# WKUP_CTRL_MMR0_CFG0 register map
Vendor: Texas Instruments
Registers are 32-bit, access per field, reset 0x0 unless marked. A register's access mark holds for its fields unless they carry their own. Offsets are as the file gives them; [hi:lo] are bit positions; lines under a group give offsets from that group; {n}, {i} and the like mark numbered series; 'fields as' and 'values as' point back to an identical list.

## WKUP_CTRL_MMR0_CFG0 (part 2 of 2)
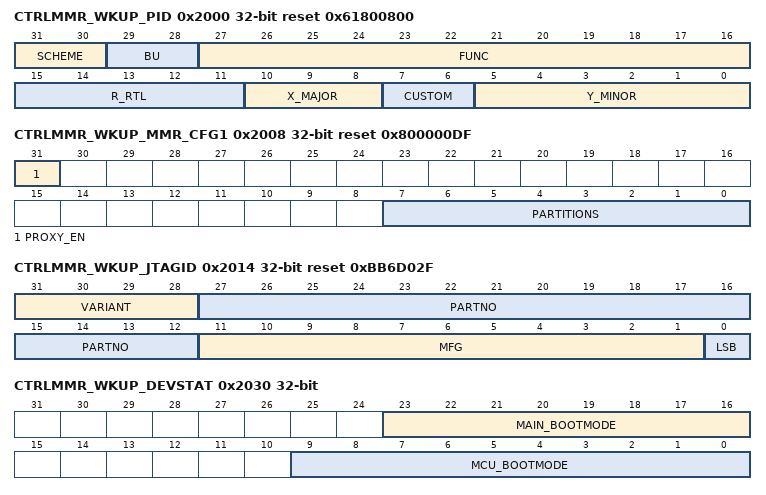
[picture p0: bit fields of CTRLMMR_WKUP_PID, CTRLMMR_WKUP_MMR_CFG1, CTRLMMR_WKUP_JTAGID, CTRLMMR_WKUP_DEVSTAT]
0x2000 CTRLMMR_WKUP_PID ro reset 0x61800800
  [31:30] SCHEME
  [29:28] BU — Business unit - Processors
  [27:16] FUNC — Module functional identifier - CTRL MMR
  [15:11] R_RTL — RTL revision number - actual value determined by RTL
  [10:8] X_MAJOR — Major revision number - actual value determined by RTL
  [7:6] CUSTOM — Custom revision number - actual value determined by RTL
  [5:0] Y_MINOR — Minor revision number - actual value determined by RTL
0x2008 CTRLMMR_WKUP_MMR_CFG1 ro reset 0x800000DF
  [31] PROXY_EN — Proxy addressing enabled
  [7:0] PARTITIONS — Indicates present partitions
0x2014 CTRLMMR_WKUP_JTAGID ro reset 0xBB6D02F
  [31:28] VARIANT — Used to indicate new PGs
  [27:12] PARTNO — Part number for boundary scan
  [11:1] MFG — Indicates manufacturer
  [0] LSB — Always 1
{0x2020+4i} CTRLMMR_WKUP_DIE_ID{i} ro reset not defined (i=0..3)
  [31:0] DIEID — Contains individual die information
0x2030 CTRLMMR_WKUP_DEVSTAT (reset mask 0xFF00FC00)
  [23:16] MAIN_BOOTMODE rw — Specifies the device Primary and Backup boot media.
  [9:0] MCU_BOOTMODE rw — Indicates MCU boot mode.
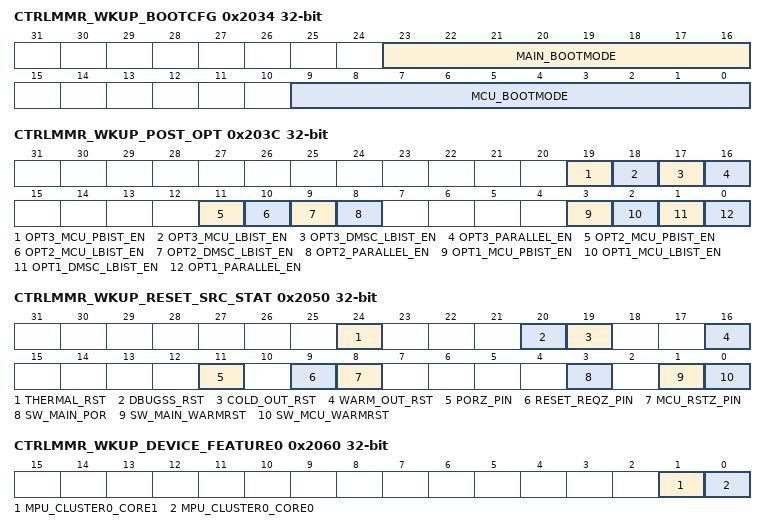
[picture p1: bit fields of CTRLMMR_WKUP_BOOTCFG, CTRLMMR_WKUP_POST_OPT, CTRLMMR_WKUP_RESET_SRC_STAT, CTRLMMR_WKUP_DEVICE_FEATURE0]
0x2034 CTRLMMR_WKUP_BOOTCFG ro (reset mask 0xFF00FC00)
  [23:16] MAIN_BOOTMODE — Specifies the device Primary and Backup boot media as latched at PORz
  [9:0] MCU_BOOTMODE — Indicates MCU boot mode as latched at power-on reset. These bits always contain the values latched.Bits 9:8 - Power-on Self Test mode (if
0x2038 CTRLMMR_WKUP_POST_SEL_STAT ro (reset mask 0xFFFFFFFC)
  [1:0] POST_SEL_STAT — Indicates which POST option was selected at power-up
0x203C CTRLMMR_WKUP_POST_OPT ro (reset mask 0xFFF0F0F0)
  [19] OPT3_MCU_PBIST_EN — MCU R5 PBIST enabled
  [18] OPT3_MCU_LBIST_EN — MCU R5 LBIST enabled
  [17] OPT3_DMSC_LBIST_EN — DMSC LBIST enabled
  [16] OPT3_PARALLEL_EN — Selects DMSC/MCU R5 LBIST sequencing
  [11] OPT2_MCU_PBIST_EN — MCU R5 PBIST enabled
  [10] OPT2_MCU_LBIST_EN — MCU R5 LBIST enabled
  [9] OPT2_DMSC_LBIST_EN — DMSC LBIST enabled
  [8] OPT2_PARALLEL_EN — Selects DMSC/MCU R5 LBIST sequencing
  [3] OPT1_MCU_PBIST_EN — MCU R5 PBIST enabled
  [2] OPT1_MCU_LBIST_EN — MCU R5 LBIST enabled
  [1] OPT1_DMSC_LBIST_EN — DMSC LBIST enabled
  [0] OPT1_PARALLEL_EN — Selects DMSC/MCU R5 LBIST sequencing
0x2050 CTRLMMR_WKUP_RESET_SRC_STAT access not given
  [24] THERMAL_RST — When set, indicates that a VTM Max Temp Thermal reset occurred. (access REC)
  [20] DBUGSS_RST — When set, indicates that a Debug reset occurred. (access FEC)
  [19] COLD_OUT_RST — When set, indicates that a DMSC Cold reset occurred. (access FEC)
  [16] WARM_OUT_RST — When set, indicates that a DSMC Warm reset occurred. (access FEC)
  [11] PORZ_PIN — When set indicates that a PORz pin reset occurred. (access FEC)
  [9] RESET_REQZ_PIN — When set indicates that a RESET_REQz pin reset occurred. (access FEC)
  [8] MCU_RSTZ_PIN — When set indicates that a MCU_RESETz pin reset occurred. (access FEC)
  [3] SW_MAIN_POR — When set, indicates that a Software MAIN Power-on reset occurred. (access FEC)
  [1] SW_MAIN_WARMRST — When set indicates that a Software MAIN Warm reset occurred. (access FEC)
  [0] SW_MCU_WARMRST — When set indicates that a Software MCU Warm reset occurred. (access FEC)
0x2060 CTRLMMR_WKUP_DEVICE_FEATURE0 ro (reset mask 0xFFFFFFFC)
  [1] MPU_CLUSTER0_CORE1 — MPU Cluster0 Core 1 is enabled when set
  [0] MPU_CLUSTER0_CORE0 — MPU Cluster0 Core 0 is enabled when set
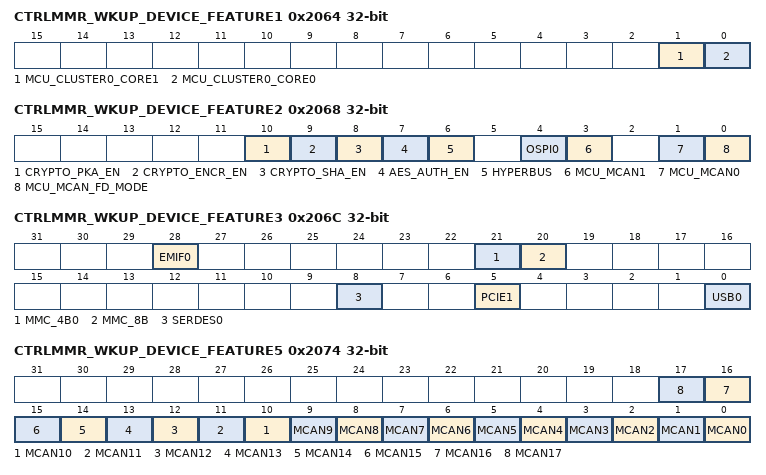
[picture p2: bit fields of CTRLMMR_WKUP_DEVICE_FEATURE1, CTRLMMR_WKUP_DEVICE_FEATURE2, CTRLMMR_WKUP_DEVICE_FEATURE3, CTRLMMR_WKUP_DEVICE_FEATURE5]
0x2064 CTRLMMR_WKUP_DEVICE_FEATURE1 ro (reset mask 0xFFFFFFFC)
  [1] MCU_CLUSTER0_CORE1 — MAIN MCU Cluster0 Core1 is enabled when set
  [0] MCU_CLUSTER0_CORE0 — MAIN MCU Cluster0 Core0 is enabled when set
0x2068 CTRLMMR_WKUP_DEVICE_FEATURE2 ro (reset mask 0xFFFFF804)
  [10] CRYPTO_PKA_EN — MCU SA2_UL Crypto Module PKA enabled
  [9] CRYPTO_ENCR_EN — MCU SA2_UL Crypto Module AES/3DES/DBRG enabled
  [8] CRYPTO_SHA_EN — MCU SA2_UL Crypto Module SHA/MD5 enabled
  [7] AES_AUTH_EN — AES authentication is enabled in MCU_FlashSS and DMSC when set
  [6] HYPERBUS — MCU_Hyperbus is enabled when set
  [4] OSPI0 — MCU_OSPI0 is enabled when set
  [3] MCU_MCAN1 — MCU_MCAN1 is enabled when set
  [1] MCU_MCAN0 — MCU_MCAN0 is enabled when set
  [0] MCU_MCAN_FD_MODE — FD mode is supported on MCU_MCAN[1:0] when set
0x206C CTRLMMR_WKUP_DEVICE_FEATURE3 ro (reset mask 0xEFCFFEDE)
  [28] EMIF0 — EMIF0 is enabled when set
  [21] MMC_4B0 — 4-bit MMC/SD1 is enabled when set
  [20] MMC_8B — 8-bit MMC/SD0 is enabled when set
  [8] SERDES0 — 10G SERDES0 is enabled when set
  [5] PCIE1 — PCIe1 is enabled when set
  [0] USB0 — USB0 is enabled when set
0x2074 CTRLMMR_WKUP_DEVICE_FEATURE5 ro (reset mask 0xFFFC0000)
  [n] MCAN{n} (n=0..17) — MCAN{n} is enabled when set
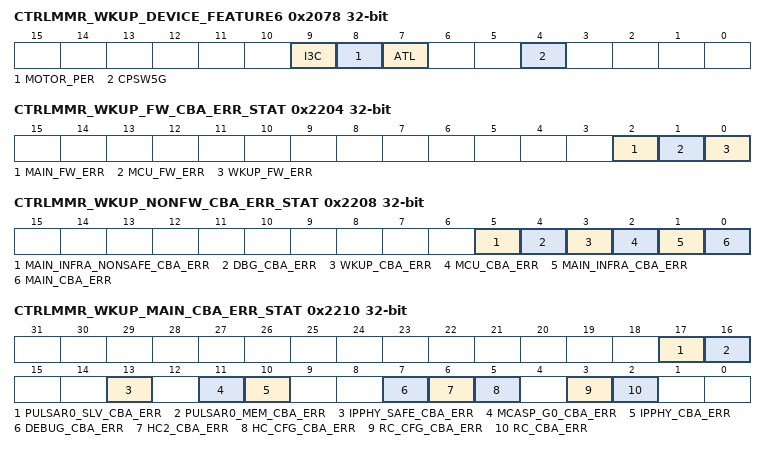
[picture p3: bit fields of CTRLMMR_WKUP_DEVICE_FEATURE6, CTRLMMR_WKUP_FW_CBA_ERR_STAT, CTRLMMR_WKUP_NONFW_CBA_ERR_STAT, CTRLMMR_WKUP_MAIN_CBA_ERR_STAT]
0x2078 CTRLMMR_WKUP_DEVICE_FEATURE6 ro (reset mask 0xFF8FFC6F)
  [9] I3C — MAIN domain I3C is enabled when set
  [8] MOTOR_PER — Motor control peripherals (eCAP, eQEP, eHRPWM) are enabled when set
  [7] ATL — Audio tracking logic is enabled when set
  [4] CPSW5G — 4 Channel Q/SGMII Ethernet switch enabled when set
0x2200 CTRLMMR_WKUP_DBG_CBA_ERR_STAT ro (reset mask 0xFFFFFFFD)
  [1] MAIN_DBG_ERR — Main Debug bus segment error
0x2204 CTRLMMR_WKUP_FW_CBA_ERR_STAT ro (reset mask 0xFFFFFFF8)
  [2] MAIN_FW_ERR — MAIN Firewall bus segment error
  [1] MCU_FW_ERR — MCU Firewall bus segment error
  [0] WKUP_FW_ERR — WKUP Firewall bus segment error
0x2208 CTRLMMR_WKUP_NONFW_CBA_ERR_STAT ro (reset mask 0xFFFFFFC0)
  [5] MAIN_INFRA_NONSAFE_CBA_ERR — MAIN Infrastructure non-safe bus segment error
  [4] DBG_CBA_ERR — Debug bus aggregated error. See
  [3] WKUP_CBA_ERR — WKUP Data bus segment error
  [2] MCU_CBA_ERR — MCU Data bus segment error
  [1] MAIN_INFRA_CBA_ERR — MAIN Infrastructure safe bus segment error
  [0] MAIN_CBA_ERR — MAIN Data bus aggregated error. See
0x2210 CTRLMMR_WKUP_MAIN_CBA_ERR_STAT ro (reset mask 0xFFFCD313)
  [17] PULSAR0_SLV_CBA_ERR — MAIN R5 Slave Data bus segment error
  [16] PULSAR0_MEM_CBA_ERR — MAIN R5 Memory Data bus segment error
  [13] IPPHY_SAFE_CBA_ERR — MAIN Phy safe Data bus segment error
  [11] MCASP_G0_CBA_ERR — MAIN McASP Group0 Data bus segment error
  [10] IPPHY_CBA_ERR — MAIN Phy non-safe Data bus segment error
  [7] DEBUG_CBA_ERR — MAIN Debug Data bus segment error
  [6] HC2_CBA_ERR — MAIN HC2 Data bus segment error
  [5] HC_CFG_CBA_ERR — MAIN HC CFG Data bus segment error
  [3] RC_CFG_CBA_ERR — MAIN RC CFG Data bus segment error
  [2] RC_CBA_ERR — MAIN RC Data bus segment error
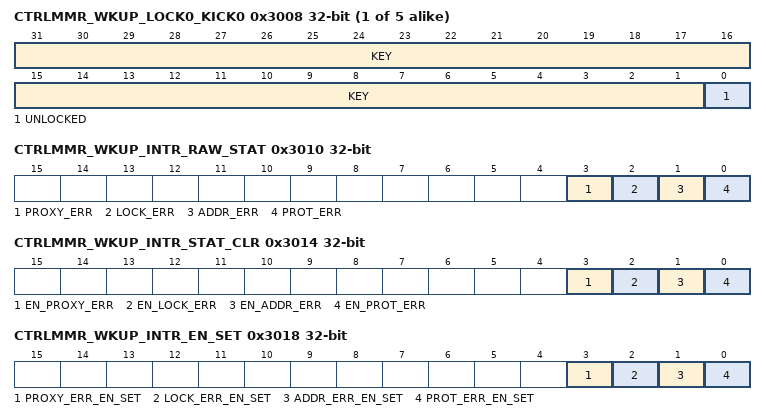
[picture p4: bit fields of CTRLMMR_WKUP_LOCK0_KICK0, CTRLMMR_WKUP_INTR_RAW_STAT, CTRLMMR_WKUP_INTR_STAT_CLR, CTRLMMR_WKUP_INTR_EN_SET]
{0x3008+0x4000*i} CTRLMMR_WKUP_LOCK{i}_KICK0 (i=0..4)
  [31:1] KEY rw — Write the kick0 unlock value followed by the kick1 unlock value to unlock the write-protected Partition{i} registers
  [0] UNLOCKED ro — Unlock status.
{0x300C+0x4000*i} CTRLMMR_WKUP_LOCK{i}_KICK1 rw (i=0..4)
  [31:0] KEY — Write the kick1 unlock value after the kick0 unlock value to unlock the write-protected Partition{i} registers
0x3010 CTRLMMR_WKUP_INTR_RAW_STAT access not given
  [3] PROXY_ERR — Proxy violation occurred (attempt to write a Proxy1 claimed register through its Proxy0 address) (access W1TS)
  [2] LOCK_ERR — Lock violation occurred (attempt to write a write-locked register with partition locked) (access W1TS)
  [1] ADDR_ERR — Address violation occurred (attempt to read or write an invalid register address) (access W1TS)
  [0] PROT_ERR — Protection violation occurred (attempt to read or write a register with insufficient security or privilege access rights) (access W1TS)
0x3014 CTRLMMR_WKUP_INTR_STAT_CLR access not given
  [3] EN_PROXY_ERR — Enabled proxy interrupt event status (access W1TC)
  [2] EN_LOCK_ERR — Enabled lock interrupt event status (access W1TC)
  [1] EN_ADDR_ERR — Enabled address interrupt event status (access W1TC)
  [0] EN_PROT_ERR — Enabled protection interrupt event status (access W1TC)
0x3018 CTRLMMR_WKUP_INTR_EN_SET access not given
  [3] PROXY_ERR_EN_SET — Proxy interrupt enable (access W1TS)
  [2] LOCK_ERR_EN_SET — Lock interrupt enable (access W1TS)
  [1] ADDR_ERR_EN_SET — Address interrupt enable (access W1TS)
  [0] PROT_ERR_EN_SET — Protection interrupt enable (access W1TS)
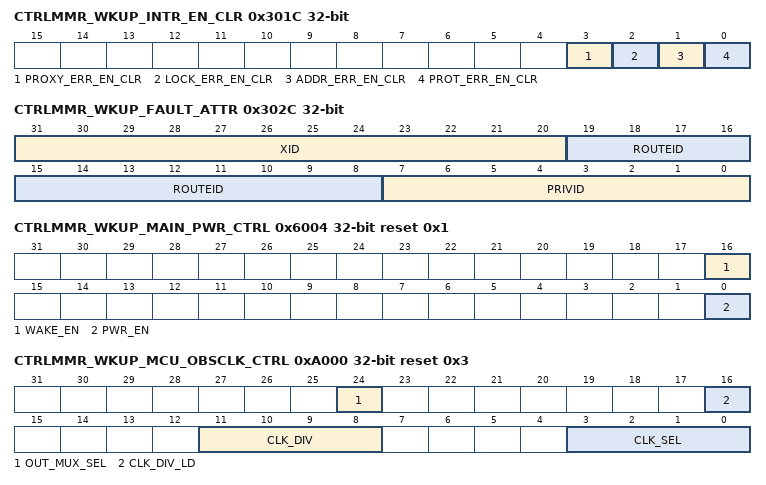
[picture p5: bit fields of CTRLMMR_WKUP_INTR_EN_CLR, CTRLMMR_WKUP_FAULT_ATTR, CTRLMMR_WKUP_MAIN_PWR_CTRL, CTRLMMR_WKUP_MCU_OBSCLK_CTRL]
0x301C CTRLMMR_WKUP_INTR_EN_CLR access not given
  [3] PROXY_ERR_EN_CLR — Proxy interrupt disable (access W1TC)
  [2] LOCK_ERR_EN_CLR — Lock interrupt disable (access W1TC)
  [1] ADDR_ERR_EN_CLR — Address interrupt disable (access W1TC)
  [0] PROT_ERR_EN_CLR — Protection interrupt disable (access W1TC)
0x3020 CTRLMMR_WKUP_EOI
  [7:0] VECTOR rw
0x3024 CTRLMMR_WKUP_FAULT_ADDR ro
  [31:0] ADDRESS — Address of the faulted access
0x3028 CTRLMMR_WKUP_FAULT_TYPE ro
  [5:0] TYPE — Type of access which faulted 0h - No fault 1h - User execute access 2h - User write access 4h - User read access 8h - Supervisor execute access 10h - Supervisor write access 20h - Supervisor read access
0x302C CTRLMMR_WKUP_FAULT_ATTR ro
  [31:20] XID — Transaction ID
  [19:8] ROUTEID
  [7:0] PRIVID — Privilege ID
0x3030 CTRLMMR_WKUP_FAULT_CLR access not given
  [0] CLEAR — Fault clear (access W1TC)
{0x3100+4i} CTRLMMR_WKUP_P0_CLAIM{i} rw (i=0..5)
  [31:0] PROXY1_CLAIMED — Proxy1 register claim bit
0x6004 CTRLMMR_WKUP_MAIN_PWR_CTRL reset 0x1
  [16] WAKE_EN rw — When set, drives the PMIC_WAKE0 output (low).
  [0] PWR_EN rw — When set, drives the PMIC_PWR_EN1 output to turn on the MAIN voltage domain
0x6008 CTRLMMR_WKUP_MCU_PWR_CTRL
  [16] WAKE_EN rw — When set, drives the PMIC_WAKE1 output (low).
0x6020 CTRLMMR_WKUP_GPIO_CTRL
  [0] WAKEN rw — Enables WKUP_GPIO wakeup event operation by controlling the WKUP_GPIO LPSC clockstop_ack behavior. 0h - No WKUP_GPIO wakeup support. WKUP_GPIO vbus clock is gated on clkstop_ack from WKUP_GPIO to LPSC 1h - WKUP_GPIO wakeup enabled. WKUP_GPIO vbus clock is NOT gated on LPSC clockstop_req. WKUP_GPIO LPSC clkstop_ack input is driven by clkstop_req output.
0x6030 CTRLMMR_WKUP_I2C0_CTRL
  [0] HS_MCS_EN rw — HS Mode master current source enable.
{0x6080+4i} CTRLMMR_WKUP_DBOUNCE_CFG{i} (i=1..6)
  [5:0] DB_CFG rw — Configures the debounce period used for I/Os with DEBOUNCE_SEL{i} enabled.
0x7100 CTRLMMR_WKUP_P1_CLAIM0 rw
  [31:0] PROXY1_CLAIMED — Proxy1 register claim bit
0x7104 CTRLMMR_WKUP_P1_CLAIM1 rw
  [31:0] PROXY1_CLAIMED — Proxy1 register claim bit
0xA000 CTRLMMR_WKUP_MCU_OBSCLK_CTRL reset 0x3
  [24] OUT_MUX_SEL rw — MCU_OBSCLK pin output mux selection.
  [16] CLK_DIV_LD rw — Load the output divider value
  [11:8] CLK_DIV rw — MCU_OBSCLK pin clock selection output divider
  [3:0] CLK_SEL rw — MCU_OBSCLK pin clock selection 0h - CLK_12M_RC 1h - '0' 2h - MCU_PLL0_HSDIV0_CLKOUT 3h - MCU_PLLCTL_OBSCLK 4h - MCU_PLL1_HSDIV1_CLKOUT 5h - MCU_PLL1_HSDIV2_CLKOUT 6h - MCU_PLL1_HSDIV3_CLKOUT 7h - MCU_PLL1_HSDIV4_CLKOUT 8h - MCU_PLL2_HSDIV0_CLKOUT 9h - CLK_32K Ah - MCU_PLL2_HSDIV1_CLKOUT Bh - MCU_PLL2_HSDIV2_CLKOUT Ch - MCU_PLL2_HSDIV3_CLKOUT Dh - MCU_PLL2_HSDIV4_CLKOUT Eh - HFOSC0_CLKOUT Fh - WKUP_LFOSC0_CLKOUT
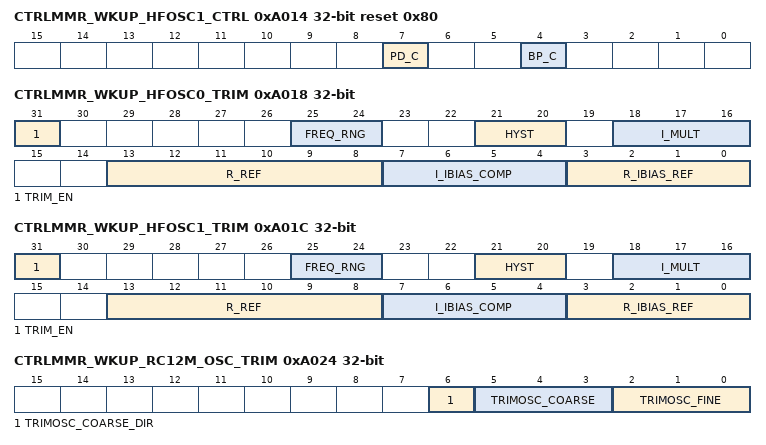
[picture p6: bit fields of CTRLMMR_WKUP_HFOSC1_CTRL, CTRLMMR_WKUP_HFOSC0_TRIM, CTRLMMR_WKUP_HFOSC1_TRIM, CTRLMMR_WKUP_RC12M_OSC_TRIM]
0xA014 CTRLMMR_WKUP_HFOSC1_CTRL reset 0x80
  [7] PD_C rw — Oscillator powerdown control. When set, oscillator is disabled. Oscillator output is tristated if bp_c=0
  [4] BP_C rw — Oscillator bypass control. When set oscillator is in bypass mode
0xA018 CTRLMMR_WKUP_HFOSC0_TRIM (reset mask 0x7CC8C000)
  [31] TRIM_EN rw — Apply MMR values to OSC trim inputs instead of tie-offs
  [25:24] FREQ_RNG rw — Sets the frequency range of operation based on: 0h - I(AMP) - 3x I(MIRRBIAS) 1h - I(AMP) 2h - I(AMP) 3h - I(AMP) + 3x I(MIRRBIAS)
  [21:20] HYST rw — Sets comparator hysteresis
  [18:16] I_MULT rw — AGC AMP current multiplication gain 0h - 3x I(MIRRBIAS) 1h - 4x I(MIRRBIAS) 2h - 5x I(MIRRBIAS) 3h - 6x I(MIRRBIAS) 4h - 7x I(MIRRBIAS) 5h - 8x I(MIRRBIAS) 6h - 9x I(MIRRBIAS) 7h - 10x I(MIRRBIAS)
  [13:8] R_REF rw — Sets the AMP AGC bias current 0h - 0.00 K-Ohm 1h - 3.1548 K-Ohm 2h - 6.3048 K-Ohm 3h - 9.4548 K-Ohm 4h - 12.6048 K-Ohm 5h - 15.7548 K-Ohm 6h - 18.9048 K-Ohm 7h - 22.0548 K-Ohm
  [7:4] I_IBIAS_COMP rw — Sets the COMP bias current 0h - 40x 1h - 48x 2h - 56x 3h - 64x 4h - 72x 5h - 80x 6h - 88x 7h - 96x 8h - 104x 9h - 112x Ah - 120x Bh - 128x Ch - 136x Dh - 144x Eh - 152x Fh - 160x
  [3:0] R_IBIAS_REF rw — Sets the base IBIAS reference 0h - 64 K-Ohm 1h - 72 K-Ohm 2h - 80 K-Ohm 3h - 88 K-Ohm 4h - 96 K-Ohm 5h - 104 K-Ohm 6h - 112 K-Ohm 7h - 120 K-Ohm 8h - 128 K-Ohm 9h - 136 K-Ohm Ah - 144 K-Ohm Bh - 152 K-Ohm Ch - 160 K-Ohm Dh - 168 K-Ohm Eh - 176 K-Ohm Fh - 184 K-Ohm
0xA01C CTRLMMR_WKUP_HFOSC1_TRIM (reset mask 0x7CC8C000)
  fields as CTRLMMR_WKUP_HFOSC0_TRIM
0xA024 CTRLMMR_WKUP_RC12M_OSC_TRIM (reset mask 0xFFFFFF80)
  [6] TRIMOSC_COARSE_DIR rw — Coarse adjustment direction. If output is greater than 12.5
  [5:3] TRIMOSC_COARSE rw — Coarse adjustment. Frequency is decreased or increased by 1.25 MHz per value based on the trimosc_coarse_dir value.
  [2:0] TRIMOSC_FINE rw — Fine adjustment. Decreases the frequency by 250 KHz per value.
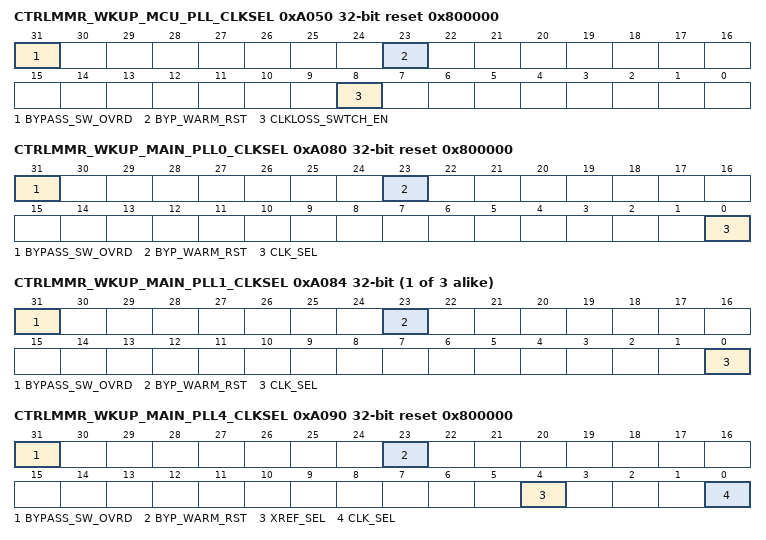
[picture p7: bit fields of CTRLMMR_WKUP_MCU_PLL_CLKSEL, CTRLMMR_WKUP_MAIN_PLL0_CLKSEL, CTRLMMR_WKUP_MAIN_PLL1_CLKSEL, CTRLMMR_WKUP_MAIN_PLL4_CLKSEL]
0xA050 CTRLMMR_WKUP_MCU_PLL_CLKSEL reset 0x800000
  [31] BYPASS_SW_OVRD rw — PLL Bypass warm reset software override
  [23] BYP_WARM_RST rw — PLL bypass mode after warm reset.
  [8] CLKLOSS_SWTCH_EN rw — When set, enables automatic switching of MCU PLL[2:0] clock source to CLK_12M_RC if HFOSC0 clock loss is detected
0xA060 CTRLMMR_WKUP_PER_CLKSEL
  [0] MCUPLL_BYPASS rw — Select the main oscillator clock rather than the PLL generated clock as the functional clock (PLL BYPASS mode).
0xA064 CTRLMMR_WKUP_USART_CLKSEL
  [0] CLK_SEL rw — WKUP_USART0 FCLK selection
0xA070 CTRLMMR_WKUP_GPIO_CLKSEL
  [1:0] WAKE_CLK_SEL rw — WKUP_GPIO clock selection. Must be set to MCU_SYSCLK0/6 whenever WKUP_GPIO VBUS interface is enabled. Other clock source may be selected as a wake up clock for DeepSleep modes after WKUP_GPIO is gated off through LPSC. 0h - MCU_SYSCLK0 / 6 1h - MCU_SYSCLK0 / 6 2h - CLK_32K 3h - CLK_12M_RC
0xA080 CTRLMMR_WKUP_MAIN_PLL0_CLKSEL reset 0x800000
  [31] BYPASS_SW_OVRD rw — PLL Bypass warm reset software override
  [23] BYP_WARM_RST rw — PLL bypass mode after warm reset.
  [0] CLK_SEL rw — Selects the clock source for MAIN PLL0
{0xA080+4i} CTRLMMR_WKUP_MAIN_PLL{i}_CLKSEL (i=1..3)
  [31] BYPASS_SW_OVRD rw — PLL Bypass warm reset software override
  [23] BYP_WARM_RST rw — PLL bypass mode after warm reset.
  [0] CLK_SEL rw — Selects the clock source for MAIN PLL{i}
0xA090 CTRLMMR_WKUP_MAIN_PLL4_CLKSEL reset 0x800000
  [31] BYPASS_SW_OVRD rw — PLL Bypass warm reset software override
  [23] BYP_WARM_RST rw — PLL bypass mode after warm reset.
  [4] XREF_SEL rw — Selects the alternate clock source for MAIN PLL4
  [0] CLK_SEL rw — Selects the clock source for MAIN PLL4
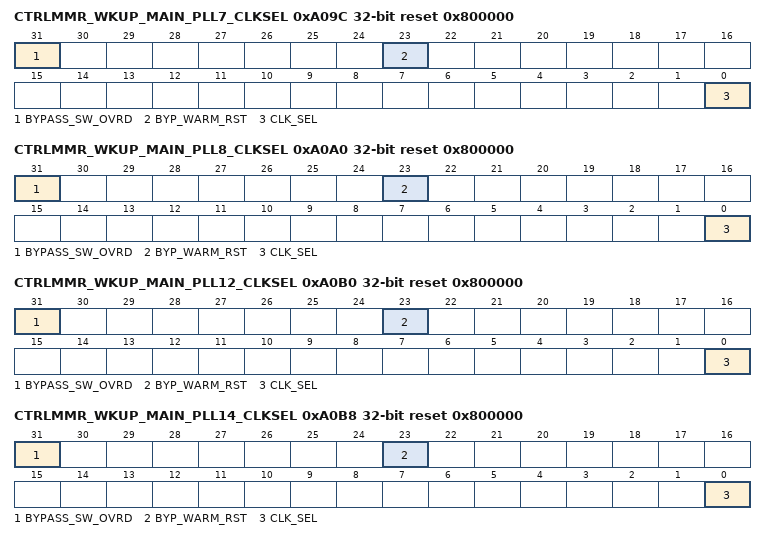
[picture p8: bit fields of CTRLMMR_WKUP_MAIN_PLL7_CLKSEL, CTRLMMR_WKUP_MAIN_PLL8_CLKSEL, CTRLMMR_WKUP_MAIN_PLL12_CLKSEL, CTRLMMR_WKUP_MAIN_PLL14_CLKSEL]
0xA09C CTRLMMR_WKUP_MAIN_PLL7_CLKSEL reset 0x800000
  [31] BYPASS_SW_OVRD rw — PLL Bypass warm reset software override
  [23] BYP_WARM_RST rw — PLL bypass mode after warm reset.
  [0] CLK_SEL rw — Selects the clock source for MAIN PLL7
0xA0A0 CTRLMMR_WKUP_MAIN_PLL8_CLKSEL reset 0x800000
  [31] BYPASS_SW_OVRD rw — PLL Bypass warm reset software override
  [23] BYP_WARM_RST rw — PLL bypass mode after warm reset.
  [0] CLK_SEL rw — Selects the clock source for MAIN PLL8
0xA0B0 CTRLMMR_WKUP_MAIN_PLL12_CLKSEL reset 0x800000
  [31] BYPASS_SW_OVRD rw — PLL Bypass warm reset software override
  [23] BYP_WARM_RST rw — PLL bypass mode after warm reset.
  [0] CLK_SEL rw — Selects the clock source for MAIN PLL12
0xA0B8 CTRLMMR_WKUP_MAIN_PLL14_CLKSEL reset 0x800000
  [31] BYPASS_SW_OVRD rw — PLL Bypass warm reset software override
  [23] BYP_WARM_RST rw — PLL bypass mode after warm reset.
  [0] CLK_SEL rw — Selects the clock source for MAIN PLL14
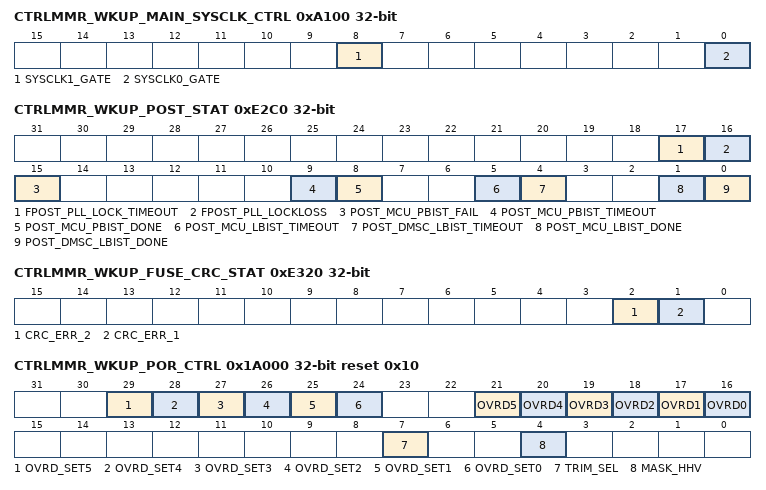
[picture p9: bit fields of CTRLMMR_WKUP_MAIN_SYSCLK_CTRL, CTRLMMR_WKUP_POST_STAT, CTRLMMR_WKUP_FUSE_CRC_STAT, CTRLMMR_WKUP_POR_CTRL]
0xA100 CTRLMMR_WKUP_MAIN_SYSCLK_CTRL
  [8] SYSCLK1_GATE rw — When set, gates off SYSCLK1 output of the MAIN PLL Controller
  [0] SYSCLK0_GATE rw — When set, gates off SYSCLK0 (MCLK1) output of the MAIN PLL Controller
0xA110 CTRLMMR_WKUP_MCU_SPI0_CLKSEL
  [16] MSTR_LB_CLKSEL rw — Master mode receive capture clock loopback selection
0xA114 CTRLMMR_WKUP_MCU_SPI1_CLKSEL
  fields as CTRLMMR_WKUP_MCU_SPI0_CLKSEL
{0xB100+4i} CTRLMMR_WKUP_P2_CLAIM{i} rw (i=0..2)
  [31:0] PROXY1_CLAIMED — Proxy1 register claim bit
0xE280 CTRLMMR_WKUP_DMSC_LBIST_SIG ro reset not defined
  [31:0] MISR_SIG — MISR signature
0xE2C0 CTRLMMR_WKUP_POST_STAT ro (reset mask 0xFFFC7CCC)
  [17] FPOST_PLL_LOCK_TIMEOUT — Indicates PLL lock timeout for Fast POST mode operation.
  [16] FPOST_PLL_LOCKLOSS — Indicates if PLL lock was lost during POST
  [15] POST_MCU_PBIST_FAIL — MCU PBIST failed
  [9] POST_MCU_PBIST_TIMEOUT — MCU PBIST timed out
  [8] POST_MCU_PBIST_DONE — MCU PBIST done
  [5] POST_MCU_LBIST_TIMEOUT — MCU LBIST timed out
  [4] POST_DMSC_LBIST_TIMEOUT — DMSC LBIST timed out
  [1] POST_MCU_LBIST_DONE — MCU LBIST done
  [0] POST_DMSC_LBIST_DONE — DMSC LBIST done
0xE320 CTRLMMR_WKUP_FUSE_CRC_STAT ro (reset mask 0xFFFFFFF9)
  [2] CRC_ERR_2 — Indicates eFuse CRC error on chain 2
  [1] CRC_ERR_1 — Indicates eFuse CRC error on chain 1
{0xF100+4i} CTRLMMR_WKUP_P3_CLAIM{i} rw (i=1..6)
  [31:0] PROXY1_CLAIMED — Proxy1 register claim bit
0x13108 CTRLMMR_WKUP_P4_CLAIM2 rw
  [31:0] PROXY1_CLAIMED — Proxy1 register claim bit
0x1310C CTRLMMR_WKUP_P4_CLAIM3 rw
  [31:0] PROXY1_CLAIMED — Proxy1 register claim bit
0x13114 CTRLMMR_WKUP_P4_CLAIM5 rw
  [31:0] PROXY1_CLAIMED — Proxy1 register claim bit
0x1311C CTRLMMR_WKUP_P4_CLAIM7 rw
  [31:0] PROXY1_CLAIMED — Proxy1 register claim bit
0x1A000 CTRLMMR_WKUP_POR_CTRL reset 0x10
  [29] OVRD_SET5 rw — Reserved override set
  [28] OVRD_SET4 rw — POKLVB override set
  [27] OVRD_SET3 rw — POKLVA override set
  [26] OVRD_SET2 rw — POKHV override set
  [25] OVRD_SET1 rw — BGOK override set
  [24] OVRD_SET0 rw — PORHV override set
  [21] OVRD5 rw — Reserved override enable
  [20] OVRD4 rw — POKLVB override enable
  [19] OVRD3 rw — POKLVA override enable
  [18] OVRD2 rw — POKHV override enable
  [17] OVRD1 rw — BGOK override enable
  [16] OVRD0 rw — PORHV override enable
  [7] TRIM_SEL rw — POR Trim Select
  [4] MASK_HHV rw — Mask HHV/SOC_PORz outputs when applying new trim values
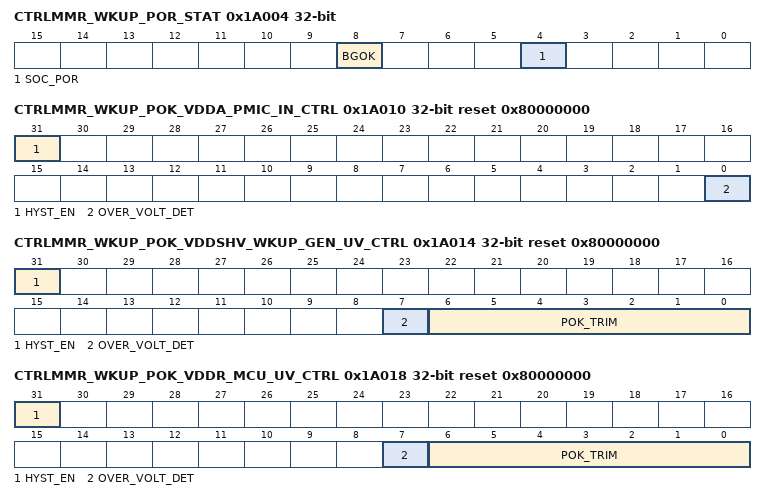
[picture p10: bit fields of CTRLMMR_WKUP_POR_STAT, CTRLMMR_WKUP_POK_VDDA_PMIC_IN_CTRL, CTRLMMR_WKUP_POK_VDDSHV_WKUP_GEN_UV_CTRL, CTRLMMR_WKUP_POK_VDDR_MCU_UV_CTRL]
0x1A004 CTRLMMR_WKUP_POR_STAT ro (reset mask 0xFFFFFEEF)
  [8] BGOK — Bandgap OK status
  [4] SOC_POR — POR module status
0x1A010 CTRLMMR_WKUP_POK_VDDA_PMIC_IN_CTRL reset 0x80000000
  [31] HYST_EN rw — Enable POK hysteresis
  [0] OVER_VOLT_DET rw — Over / under voltage detection mode
0x1A014 CTRLMMR_WKUP_POK_VDDSHV_WKUP_GEN_UV_CTRL reset 0x80000000 (reset mask 0xFFFFFF00)
  [31] HYST_EN rw — Enable POK hysteresis
  [7] OVER_VOLT_DET rw — Over / under voltage detection mode
  [6:0] POK_TRIM rw — POK trim bits. These bits are used to trim the comparator threshold voltage.
0x1A018 CTRLMMR_WKUP_POK_VDDR_MCU_UV_CTRL reset 0x80000000 (reset mask 0xFFFFFF00)
  fields as CTRLMMR_WKUP_POK_VDDSHV_WKUP_GEN_UV_CTRL
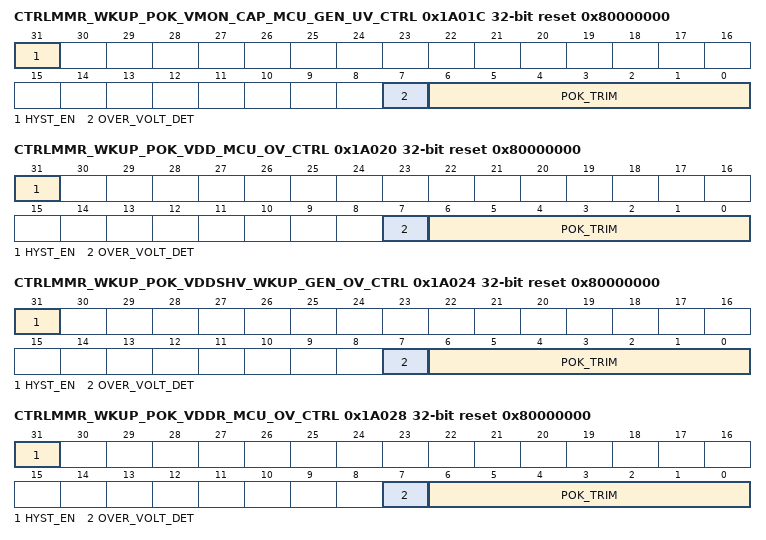
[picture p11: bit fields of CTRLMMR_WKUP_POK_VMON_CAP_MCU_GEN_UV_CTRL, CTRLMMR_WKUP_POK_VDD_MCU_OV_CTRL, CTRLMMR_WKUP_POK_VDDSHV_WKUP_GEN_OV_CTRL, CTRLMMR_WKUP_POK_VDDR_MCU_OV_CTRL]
0x1A01C CTRLMMR_WKUP_POK_VMON_CAP_MCU_GEN_UV_CTRL reset 0x80000000 (reset mask 0xFFFFFF00)
  fields as CTRLMMR_WKUP_POK_VDDSHV_WKUP_GEN_UV_CTRL
0x1A020 CTRLMMR_WKUP_POK_VDD_MCU_OV_CTRL reset 0x80000000 (reset mask 0xFFFFFF00)
  fields as CTRLMMR_WKUP_POK_VDDSHV_WKUP_GEN_UV_CTRL
0x1A024 CTRLMMR_WKUP_POK_VDDSHV_WKUP_GEN_OV_CTRL reset 0x80000000 (reset mask 0xFFFFFF00)
  fields as CTRLMMR_WKUP_POK_VDDSHV_WKUP_GEN_UV_CTRL
0x1A028 CTRLMMR_WKUP_POK_VDDR_MCU_OV_CTRL reset 0x80000000 (reset mask 0xFFFFFF00)
  fields as CTRLMMR_WKUP_POK_VDDSHV_WKUP_GEN_UV_CTRL
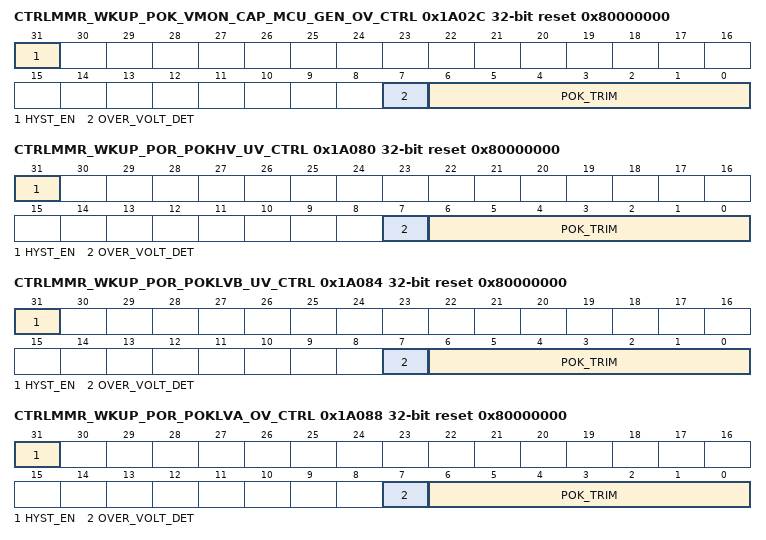
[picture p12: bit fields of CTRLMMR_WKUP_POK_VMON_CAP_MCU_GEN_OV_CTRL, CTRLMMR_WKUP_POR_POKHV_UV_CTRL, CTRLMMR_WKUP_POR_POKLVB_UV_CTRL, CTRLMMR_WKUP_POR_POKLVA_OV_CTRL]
0x1A02C CTRLMMR_WKUP_POK_VMON_CAP_MCU_GEN_OV_CTRL reset 0x80000000 (reset mask 0xFFFFFF00)
  fields as CTRLMMR_WKUP_POK_VDDSHV_WKUP_GEN_UV_CTRL
0x1A070 CTRLMMR_WKUP_MAIN_VDOM_CTRL
  [0] MAIN_VD_OFF rw — MAIN deep sleep isolation enable. This bit should be set prior to powering off the MAIN voltage domain to ensure proper signal isolation.
0x1A080 CTRLMMR_WKUP_POR_POKHV_UV_CTRL reset 0x80000000 (reset mask 0xFFFFFF00)
  fields as CTRLMMR_WKUP_POK_VDDSHV_WKUP_GEN_UV_CTRL
0x1A084 CTRLMMR_WKUP_POR_POKLVB_UV_CTRL reset 0x80000000 (reset mask 0xFFFFFF00)
  fields as CTRLMMR_WKUP_POK_VDDSHV_WKUP_GEN_UV_CTRL
0x1A088 CTRLMMR_WKUP_POR_POKLVA_OV_CTRL reset 0x80000000 (reset mask 0xFFFFFF00)
  fields as CTRLMMR_WKUP_POK_VDDSHV_WKUP_GEN_UV_CTRL
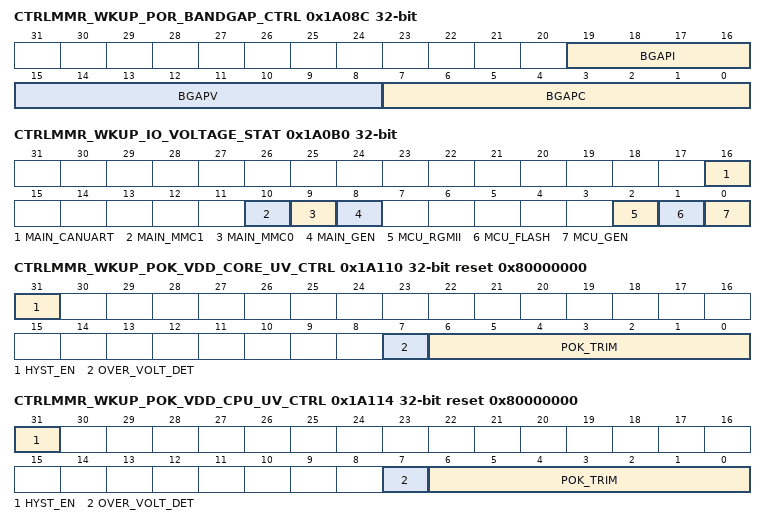
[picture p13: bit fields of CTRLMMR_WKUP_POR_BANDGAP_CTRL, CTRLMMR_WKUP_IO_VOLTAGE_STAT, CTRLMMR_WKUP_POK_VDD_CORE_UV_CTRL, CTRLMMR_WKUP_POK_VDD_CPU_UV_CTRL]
0x1A08C CTRLMMR_WKUP_POR_BANDGAP_CTRL (reset mask 0xFFF00000)
  [19:16] BGAPI rw — Bandgap output current trim bits
  [15:8] BGAPV rw — Bandgap output voltage magnitude trim bits
  [7:0] BGAPC rw — Bandgap slope trim bits. Bit7 is used to calculate the offset
0x1A0A0 CTRLMMR_WKUP_TEMP_DIODE_TRIM (reset mask 0xFFFFC000)
  [13:0] TRIM rw — Sets the diode non-ideality factor (n), starting from 100th place decimal and going down
0x1A0B0 CTRLMMR_WKUP_IO_VOLTAGE_STAT ro (reset mask 0xFFFEF8F8)
  [16] MAIN_CANUART — Indicates the voltage for the CANUART I/O group
  [10] MAIN_MMC1 — Indicates the voltage for the MMC1 I/O group
  [9] MAIN_MMC0 — Indicates the voltage for the MMC0 I/O group
  [8] MAIN_GEN — Indicates the voltage for the General I/O group
  [2] MCU_RGMII — Indicates the voltage for the MCU CPSW2G RGMII I/O group
  [1] MCU_FLASH — Indicates the voltage for the MCU Flash I/O group
  [0] MCU_GEN — Indicates the voltage for the MCU General I/O group
0x1A104 CTRLMMR_WKUP_MAIN_POR_TO_CTRL (reset mask 0xFFFFFFF8)
  [2:0] TIMEOUT_PER rw — MAIN PORz hardware timeout period. 0h - Immediate 1h - 100 microsec 2h - 200 microsec 3h - 300 microsec 4h - 400 microsec 5h - 500 microsec
0x1A110 CTRLMMR_WKUP_POK_VDD_CORE_UV_CTRL reset 0x80000000 (reset mask 0xFFFFFF00)
  fields as CTRLMMR_WKUP_POK_VDDSHV_WKUP_GEN_UV_CTRL
0x1A114 CTRLMMR_WKUP_POK_VDD_CPU_UV_CTRL reset 0x80000000 (reset mask 0xFFFFFF00)
  fields as CTRLMMR_WKUP_POK_VDDSHV_WKUP_GEN_UV_CTRL
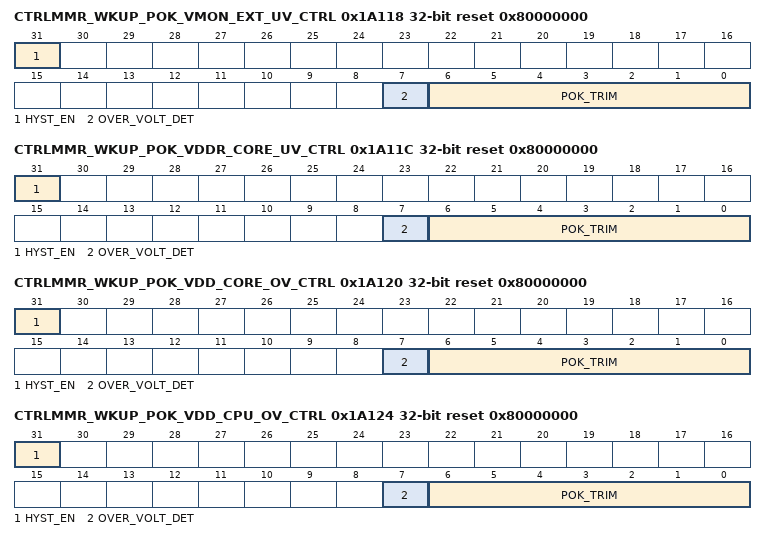
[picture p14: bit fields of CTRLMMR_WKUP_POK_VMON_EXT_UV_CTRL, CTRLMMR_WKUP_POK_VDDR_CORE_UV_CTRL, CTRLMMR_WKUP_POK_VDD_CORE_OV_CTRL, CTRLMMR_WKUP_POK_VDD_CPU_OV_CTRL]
0x1A118 CTRLMMR_WKUP_POK_VMON_EXT_UV_CTRL reset 0x80000000 (reset mask 0xFFFFFF00)
  fields as CTRLMMR_WKUP_POK_VDDSHV_WKUP_GEN_UV_CTRL
0x1A11C CTRLMMR_WKUP_POK_VDDR_CORE_UV_CTRL reset 0x80000000 (reset mask 0xFFFFFF00)
  fields as CTRLMMR_WKUP_POK_VDDSHV_WKUP_GEN_UV_CTRL
0x1A120 CTRLMMR_WKUP_POK_VDD_CORE_OV_CTRL reset 0x80000000 (reset mask 0xFFFFFF00)
  fields as CTRLMMR_WKUP_POK_VDDSHV_WKUP_GEN_UV_CTRL
0x1A124 CTRLMMR_WKUP_POK_VDD_CPU_OV_CTRL reset 0x80000000 (reset mask 0xFFFFFF00)
  fields as CTRLMMR_WKUP_POK_VDDSHV_WKUP_GEN_UV_CTRL
0x1A128 CTRLMMR_WKUP_POK_VMON_EXT_OV_CTRL reset 0x80000000 (reset mask 0xFFFFFF00)
  fields as CTRLMMR_WKUP_POK_VDDSHV_WKUP_GEN_UV_CTRL
0x1A12C CTRLMMR_WKUP_POK_VDDR_CORE_OV_CTRL reset 0x80000000 (reset mask 0xFFFFFF00)
  fields as CTRLMMR_WKUP_POK_VDDSHV_WKUP_GEN_UV_CTRL
0x1A130 CTRLMMR_WKUP_POK_VMON_EXT_MAIN1P8_UV_CTRL reset 0x80000000 (reset mask 0xFFFFFF00)
  fields as CTRLMMR_WKUP_POK_VDDSHV_WKUP_GEN_UV_CTRL
0x1A134 CTRLMMR_WKUP_POK_VMON_EXT_MAIN1P8_OV_CTRL reset 0x80000000 (reset mask 0xFFFFFF00)
  fields as CTRLMMR_WKUP_POK_VDDSHV_WKUP_GEN_UV_CTRL
0x1A138 CTRLMMR_WKUP_POK_VMON_EXT_MAIN3P3_UV_CTRL reset 0x80000000 (reset mask 0xFFFFFF00)
  fields as CTRLMMR_WKUP_POK_VDDSHV_WKUP_GEN_UV_CTRL
0x1A13C CTRLMMR_WKUP_POK_VMON_EXT_MAIN3P3_OV_CTRL reset 0x80000000 (reset mask 0xFFFFFF00)
  fields as CTRLMMR_WKUP_POK_VDDSHV_WKUP_GEN_UV_CTRL
0x1A160 CTRLMMR_WKUP_DEEPSLEEP_CTRL
  [8] FORCE_DS_MAIN rw — Force all MAIN IOs into deepsleep mode when set
  [0] FORCE_DS_WKUP rw — Force all WKUP IOs into deepsleep mode when set
0x1A170 CTRLMMR_WKUP_POR_RST_CTRL reset 0xF0000
  [24] MAIN_PORZ_DAISYCHAIN_EN rw — MAIN PORz daisy-chain event enable.
  [19:16] SW_MAIN_POR rw — Main Domain software power-on reset. When set to 6h, a power-on is issued to the MAIN voltage domain. (Bits will reset to Fh on reset of the Main Domain)
  [12] MAIN_PORZ_DS_STRETCH rw — DeepSleep mode MAIN PORz stretch.
  [0] POR_RST_ISO_DONE_Z rw — Reset isolation completion (active low). This bit should be cleared only after reset isolation of the MAIN domain is complete.
0x1A174 CTRLMMR_WKUP_MAIN_WARM_RST_CTRL reset 0xF0000
  [19:16] SW_WARMRST rw — Main Domain software warm reset. When set to 6h, a warm reset is issued to the MAIN voltage domain. (Bits will reset to Fh on reset of the Main Domain)
  [0] SOC_WARMRST_ISO_DONE_Z rw — Reset isolation completion (active low). This bit should be cleared only after reset isolation of the MAIN domain is complete.
0x1A178 CTRLMMR_WKUP_RST_STAT ro (reset mask 0xFFFEFFFE)
  [16] MCU_RST_DONE — Indicates MCU domain reset status.
  [0] MAIN_RST_DONE — Indicates MAIN domain Warm reset status.
0x1A17C CTRLMMR_WKUP_MCU_WARM_RST_CTRL reset 0xF0000
  [19:16] SW_WARMRST rw — Chip software warm reset. When set to 6h, a warm reset is issued to the device (all voltage domains). (Bits will reset to Fh on reset completion.)
0x1A180 CTRLMMR_WKUP_VDD_CPU_GLDTC_CTRL (reset mask 0xFFF8C0C0)
  [31] PWDB rw — Power down - active low.
  [30] RSTB rw — Reset - active low. To ensure proper operation, rstb must not be de-asserted for at least 100 ns after power-up (pwdb de-asserted). Additionally, rstb must be toggled low at least 200 ns after any change in threshold or low-pass filter settings to prevent abnormal trigger events.
  [18:16] LP_FILTER_SEL rw — Selects the glitch detect low-pass filter bandwidth 0h - 150 kHz 1h - 125 kHz 2h - 100 kHz 3h - 80 kHz 4h - 60 kHz 5h - 45 kHz 6h - 30 kHz 7h - 15 kHz
  [13:8] THRESH_HI_SEL rw — Selects the high voltage glitch threshold as a percentage of the monitored voltage 0h - 93.5% of VDD 1h - 94.0% of VDD 2h - 94.5% of VDD 3h - 95.0% of VDD 4h - 95.5% of VDD 5h - 96.0% of VDD 6h - 96.5% of VDD 7h - 97.0% of VDD 8h - 97.5% of VDD 9h - 98.0% of VDD Ah - 98.5% of VDD Bh - 99.0% of VDD Ch - 99.5% of VDD Dh - 100.0% of VDD Eh - 100.5% of VDD Fh - 101.0% of VDD 10h - 101.5% of VDD 11h - 102.0% of VDD 12h - 102.5% of VDD 13h - 103.0% of VDD 14h - 103.5% of VDD 15h - 104.0% of VDD 16h - 104.5% of VDD 17h - 105.0% of VDD 18h - 105.5% of VDD 19h - 106.0% of VDD 1Ah - 106.5% of VDD 1Bh - 107.0% of VDD 1Ch - 107.5% of VDD 1Dh - 108.0% of VDD 1Eh - 108.5% of VDD 1Fh - 109.0% of VDD 20h - 109.5% of VDD 21h - 110.0% of VDD 22h - 111.0% of VDD 23h - 112.0% of VDD 24h - 113.0% of VDD 25h - 114.0% of VDD 26h - 115.0% of VDD 27h - 116.0% of VDD 28h - 117.0% of VDD 29h - 118.0% of VDD 2Ah - 119.0% of VDD 2Bh - 120.0% of VDD 2Ch - 121.0% of VDD 2Dh - 122.0% of VDD 2Eh - 123.0% of VDD 2Fh - 124.0% of VDD 30h - 125.0% of VDD 31h - 126.0% of VDD 32h - 127.0% of VDD 33h - 128.0% of VDD 34h - 129.0% of VDD 35h - 130.0% of VDD 36h - 131.0% of VDD 37h - 132.0% of VDD 38h - 133.0% of VDD 39h - 134.0% of VDD 3Ah - 135.0% of VDD 3Bh - 136.0% of VDD 3Ch - 137.0% of VDD 3Dh - 138.0% of VDD 3Eh - 139.0% of VDD 3Fh - 140.0% of VDD
  [5:0] THRESH_LO_SEL rw — Selects the low voltage glitch threshold as a percentage of the monitored voltage 0h - 106.5% of VDD 1h - 106.0% of VDD 2h - 105.5% of VDD 3h - 105.0% of VDD 4h - 104.5% of VDD 5h - 104.0% of VDD 6h - 103.5% of VDD 7h - 103.0% of VDD 8h - 102.5% of VDD 9h - 102.0% of VDD Ah - 101.5% of VDD Bh - 101.0% of VDD Ch - 100.5% of VDD Dh - 100.0% of VDD Eh - 99.5% of VDD Fh - 99.0% of VDD 10h - 98.5% of VDD 11h - 98.0% of VDD 12h - 97.5% of VDD 13h - 97.0% of VDD 14h - 96.5% of VDD 15h - 96.0% of VDD 16h - 95.5% of VDD 17h - 95.0% of VDD 18h - 94.5% of VDD 19h - 94.0% of VDD 1Ah - 93.5% of VDD 1Bh - 93.0% of VDD 1Ch - 92.5% of VDD 1Dh - 92.0% of VDD 1Eh - 91.5% of VDD 1Fh - 91.0% of VDD 20h - 90.5% of VDD 21h - 90.0% of VDD 22h - 89.0% of VDD 23h - 88.0% of VDD 24h - 87.0% of VDD 25h - 86.0% of VDD 26h - 85.0% of VDD 27h - 84.0% of VDD 28h - 83.0% of VDD 29h - 82.0% of VDD 2Ah - 81.0% of VDD 2Bh - 80.0% of VDD 2Ch - 79.0% of VDD 2Dh - 78.0% of VDD 2Eh - 77.0% of VDD 2Fh - 76.0% of VDD 30h - 75.0% of VDD 31h - 74.0% of VDD 32h - 73.0% of VDD 33h - 72.0% of VDD 34h - 71.0% of VDD 35h - 70.0% of VDD 36h - 69.0% of VDD 37h - 68.0% of VDD 38h - 67.0% of VDD 39h - 66.0% of VDD 3Ah - 65.0% of VDD 3Bh - 64.0% of VDD 3Ch - 63.0% of VDD 3Dh - 62.0% of VDD 3Eh - 61.0% of VDD 3Fh - 60.0% of VDD
